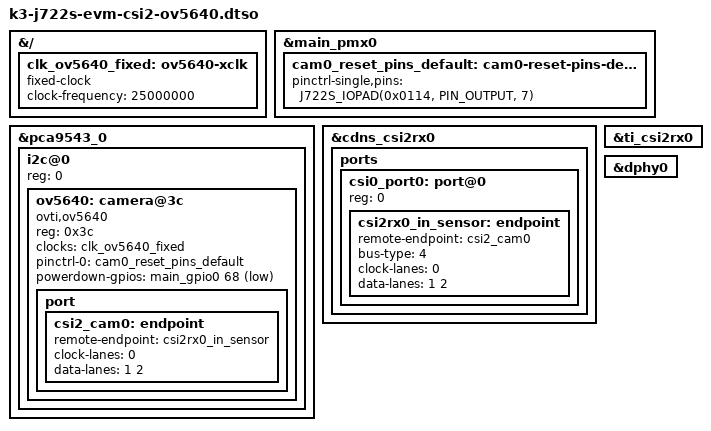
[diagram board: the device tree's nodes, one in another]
// SPDX-License-Identifier: GPL-2.0
/*
 * LI OV5640 MIPI Camera module on MIPI CSI (CSI2-EXP-AUX) connector.
 *
 * Copyright (C) 2024 Texas Instruments Incorporated - https://www.ti.com/
 */

/dts-v1/;
/plugin/;

#include <dt-bindings/gpio/gpio.h>
#include "k3-pinctrl.h"

&{/} {
	clk_ov5640_fixed: ov5640-xclk {
		compatible = "fixed-clock";
		#clock-cells = <0>;
		clock-frequency = <25000000>;
	};
};


&main_pmx0 {
	cam0_reset_pins_default: cam0-reset-pins-default {
		pinctrl-single,pins = <
			J722S_IOPAD(0x0114, PIN_OUTPUT, 7)
		>;
	};
};

&pca9543_0 {
	#address-cells = <1>;
	#size-cells = <0>;

	i2c@0 {
		#address-cells = <1>;
		#size-cells = <0>;
		reg = <0>;

		ov5640: camera@3c {
			compatible = "ovti,ov5640";
			reg = <0x3c>;

			clocks = <&clk_ov5640_fixed>;
			clock-names = "xclk";
			pinctrl-names = "default";
			pinctrl-0 = <&cam0_reset_pins_default>;
			powerdown-gpios = <&main_gpio0 68 GPIO_ACTIVE_LOW>;

			port {
				csi2_cam0: endpoint {
					remote-endpoint = <&csi2rx0_in_sensor>;
					clock-lanes = <0>;
					data-lanes = <1 2>;
				};
			};
		};
	};
};

&cdns_csi2rx0 {
	ports {
		#address-cells = <1>;
		#size-cells = <0>;

		csi0_port0: port@0 {
			reg = <0>;
			status = "okay";

			csi2rx0_in_sensor: endpoint {
				remote-endpoint = <&csi2_cam0>;
				bus-type = <4>; /* CSI2 DPHY */
				clock-lanes = <0>;
				data-lanes = <1 2>;
			};
		};
	};
};

&ti_csi2rx0 {
	status = "okay";
};

&dphy0 {
	status = "okay";
};
